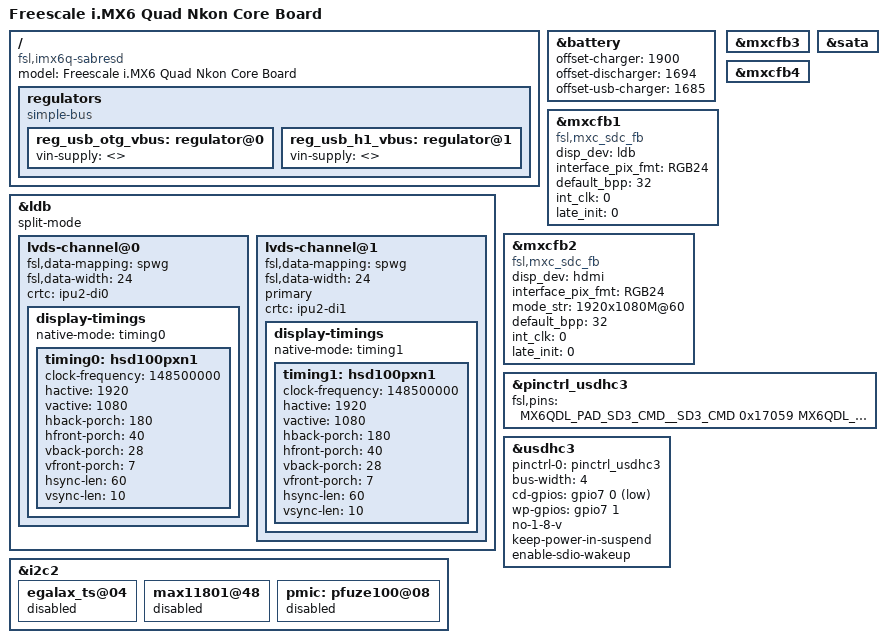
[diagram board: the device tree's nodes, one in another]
/*
 * Copyright 2012=2015 Freescale Semiconductor, Inc.
 * Copyright 2011 Linaro Ltd.
 *
 * The code contained herein is licensed under the GNU General Public
 * License. You may obtain a copy of the GNU General Public License
 * Version 2 or later at the following locations:
 *
 * http://www.opensource.org/licenses/gpl-license.html
 * http://www.gnu.org/copyleft/gpl.html
 */

/dts-v1/;

#include "imx6q.dtsi"
#include "imx6qdl-sabresd.dtsi"

/ {
	model = "Freescale i.MX6 Quad Nkon Core Board";
	compatible = "fsl,imx6q-sabresd", "fsl,imx6q";
	regulators {
		compatible = "simple-bus";
		#address-cells = <1>;
		#size-cells = <0>;

		reg_usb_otg_vbus: regulator@0 {
			vin-supply = <>;
		};

		reg_usb_h1_vbus: regulator@1 {
			vin-supply = <>;
		};
	};
};

&battery {
	offset-charger = <1900>;
	offset-discharger = <1694>;
	offset-usb-charger = <1685>;
};

&ldb {
	split-mode;
	status = "okay";

	lvds-channel@0 {
		fsl,data-mapping = "spwg";
		fsl,data-width = <24>;
		crtc = "ipu2-di0";
		status = "okay";

		display-timings {
			native-mode = <&timing0>;
			timing0: hsd100pxn1 {
				clock-frequency = <148500000>;
				hactive = <1920>;
				vactive = <1080>;
				hback-porch = <180>;
				hfront-porch = <40>;
				vback-porch = <28>;
				vfront-porch = <7>;
				hsync-len = <60>;
				vsync-len = <10>;
			};
		};
	};

	lvds-channel@1 {
		fsl,data-mapping = "spwg";
		fsl,data-width = <24>;
		primary;
		crtc = "ipu2-di1";
		status = "okay";

		display-timings {
			native-mode = <&timing1>;
			timing1: hsd100pxn1 {
				clock-frequency = <148500000>;
				hactive = <1920>;
				vactive = <1080>;
				hback-porch = <180>;
				hfront-porch = <40>;
				vback-porch = <28>;
				vfront-porch = <7>;
				hsync-len = <60>;
				vsync-len = <10>;
			};
		};
	};
};

&mxcfb1 {
	compatible = "fsl,mxc_sdc_fb";
	disp_dev = "ldb";
	interface_pix_fmt = "RGB24";
	default_bpp = <32>;
	int_clk = <0>;
	late_init = <0>;
	status = "okay";
};

&mxcfb2 {
	compatible = "fsl,mxc_sdc_fb";
	disp_dev = "hdmi";
	interface_pix_fmt = "RGB24";
	mode_str ="1920x1080M@60";
	default_bpp = <32>;
	int_clk = <0>;
	late_init = <0>;
	status = "okay";
};

&mxcfb3 {
	status = "okay";
};

&mxcfb4 {
	status = "okay";
};

&sata {
	status = "okay";
};


&pinctrl_usdhc3 {
	fsl,pins = <
		MX6QDL_PAD_SD3_CMD__SD3_CMD		0x17059
		MX6QDL_PAD_SD3_CLK__SD3_CLK		0x10059
		MX6QDL_PAD_SD3_DAT0__SD3_DATA0		0x17059
		MX6QDL_PAD_SD3_DAT1__SD3_DATA1		0x17059
		MX6QDL_PAD_SD3_DAT2__SD3_DATA2		0x17059
		MX6QDL_PAD_SD3_DAT3__SD3_DATA3		0x17059
	>;
};

&usdhc3 {
	pinctrl-names = "default";
	pinctrl-0 = <&pinctrl_usdhc3>;
	bus-width = <4>;
	cd-gpios = <&gpio7 0 GPIO_ACTIVE_LOW>;
	wp-gpios = <&gpio7 1 GPIO_ACTIVE_HIGH>;
	no-1-8-v;
	keep-power-in-suspend;
	enable-sdio-wakeup;
	status = "okay";
};


&i2c2 {
	status = "okay";

	egalax_ts@04 {
		status = "disable";
	};
	max11801@48 {
		status = "disable";
	};
	pmic: pfuze100@08 {
		status = "disable";
	};
};
